# cslr_rtcc5509_001 register map
Vendor: Texas Instruments
Peripheral module from a debugger description file.
Registers are 8-bit, read-write, no defined reset value unless marked. A register's access mark holds for its fields unless they carry their own. Offsets are as the file gives them; lines under a group give offsets from that group; [hi:lo] are bit positions; {n}, {i} and the like mark numbered series; 'fields as' and 'values as' point back to an identical list; <NAME> marks a mode.

## RTC — Real-Time Clock
0x00 RTCSEC — Seconds Register
  [7:0] SEC — Seconds select bits.
0x00 RTCSECA — Seconds Alarm Register
  [7:0] SAR — Seconds alarm select bits.
0x00 RTCMIN — Minutes Register
  [7:0] MIN — Minutes select bits.
0x00 RTCMINA — Minutes Alarm Register
  [7:0] MAR — Minutes alarm select bits.
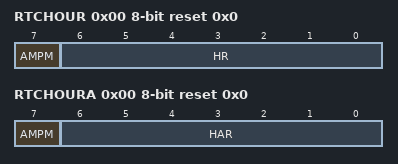
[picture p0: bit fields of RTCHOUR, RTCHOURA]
0x00 RTCHOUR reset 0x0 (reset mask 0x80) — Hours Register
  [7] AMPM — AM/PM select bit.
    0=Time is set for AM; 1=Time is set for PM
  [6:0] HR — Hours select bits.
0x00 RTCHOURA reset 0x0 (reset mask 0x80) — Hours Alarm Register
  [7] AMPM — AM/PM select bit.
    0=Alarm time is set for AM or is in 24-hour mode; 1=Alarm time is set for PM
  [6:0] HAR — Hours alarm select bits.
